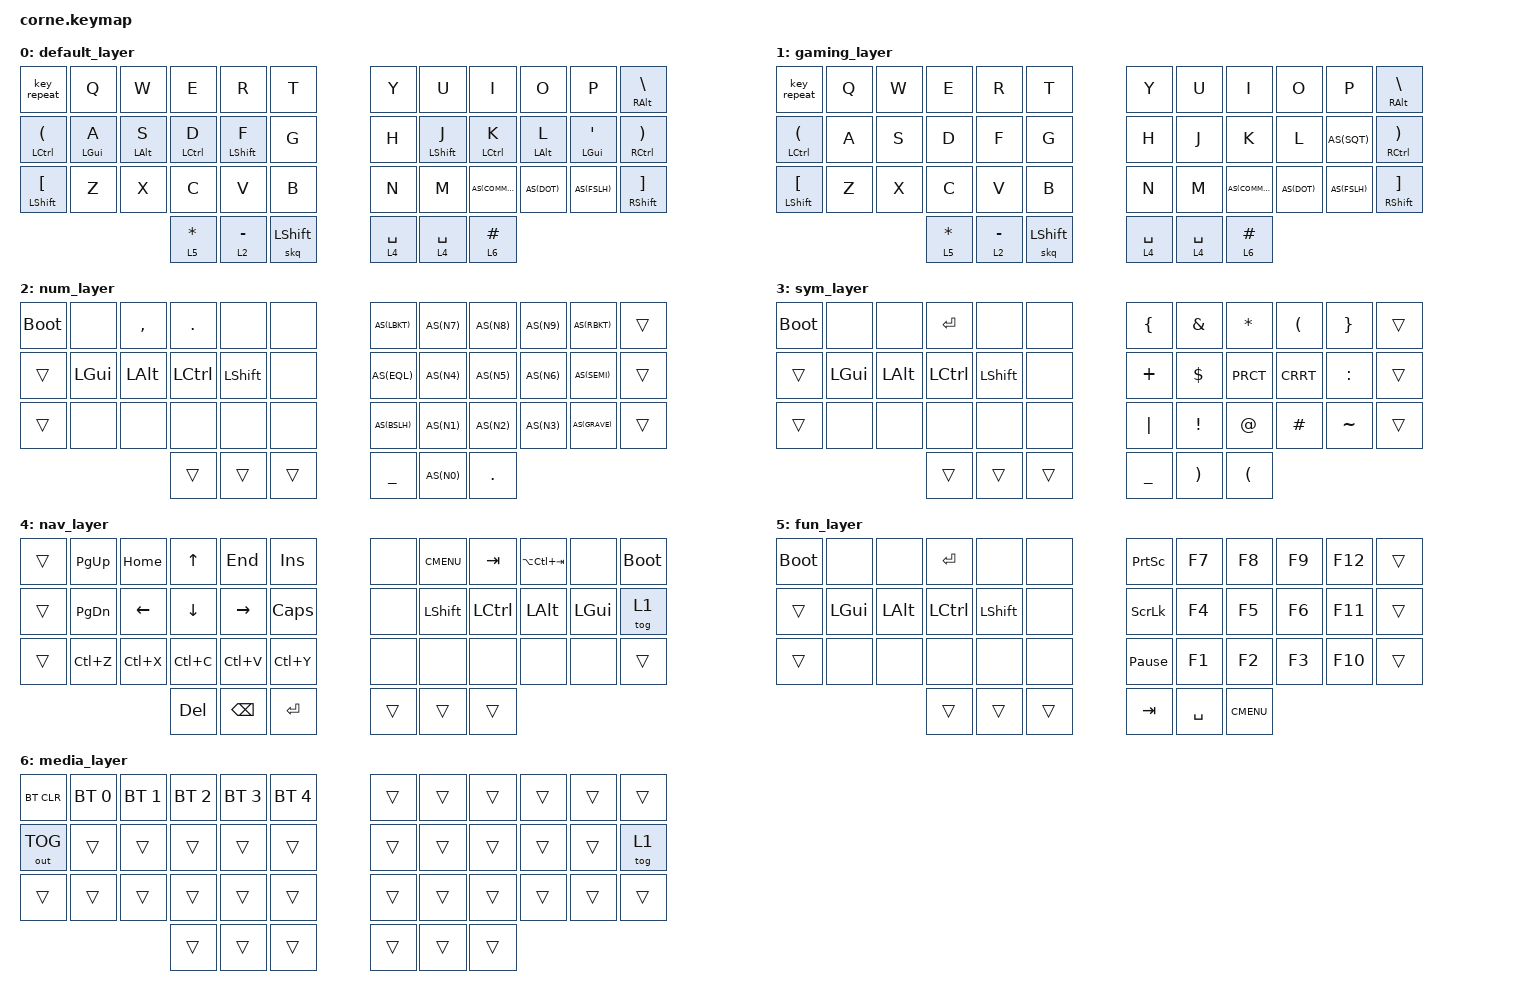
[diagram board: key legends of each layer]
/*
 * Copyright (c) 2020 The ZMK Contributors
 *
 * SPDX-License-Identifier: MIT
 */

#include <behaviors.dtsi>
#include <dt-bindings/zmk/keys.h>
#include <dt-bindings/zmk/bt.h>
#include <dt-bindings/zmk/outputs.h>


#define AS(keycode) &as LS(keycode) keycode

/ {
    behaviors {
      // auto shift behavior copied from: https://github.com/serebrov/zmk-config/blob/master/config/microdox.keymap#L23-L36
      as: auto_shift {
          compatible = "zmk,behavior-hold-tap";
          label = "AUTO_SHIFT";
          #binding-cells = <2>;
          tapping_term_ms = <200>;
          quick_tap_ms = <0>;
          flavor = "tap-preferred";
          bindings = <&kp>, <&kp>;
      };

      // Note: quick-release fixes the issue of sticky shift producing multiple upper case letters (see https://github.com/zmkfirmware/zmk/issues/903#issuecomment-909209198).
      skq: sticky_key_quick_release {
        compatible = "zmk,behavior-sticky-key";
        label = "STICKY_KEY_QUICK_RELEASE";
        #binding-cells = <1>;
        bindings = <&kp>;
        release-after-ms = <1000>;
        quick-release;
      };

      hm: homerow_mods {
          compatible = "zmk,behavior-hold-tap";
          label = "HOMEROW_MODS";
          #binding-cells = <2>;
          tapping-term-ms = <300>;
          quick-tap-ms = <0>;
          flavor = "tap-preferred";
          bindings = <&kp>, <&kp>;
      };
    };

    combos {
        compatible = "zmk,combos";
        combo_esc {
            timeout-ms = <50>;
            key-positions = <0 1>;
            bindings = <&kp ESC>;
        };

        combo_scrnsht {
            timeout-ms = <50>;
            key-positions = <1 25>;
            bindings = <&kp LG(LS(S))>;
        };

        combo_cut {
            timeout-ms = <50>;
            key-positions = <2 26>;
            bindings = <&kp LC(X)>;
        };

        combo_copy {
            timeout-ms = <50>;
            key-positions = <3 27>;
            bindings = <&kp LC(C)>;
        };

        combo_paste {
            timeout-ms = <50>;
            key-positions = <4 28>;
            bindings = <&kp LC(V)>;
        };

        combo_volmute {
            timeout-ms = <30>;
            key-positions = <13 25>;
            bindings = <&kp C_MUTE>;
        };

        combo_voldn {
            timeout-ms = <30>;
            key-positions = <14 26>;
            bindings = <&kp C_VOL_DN>;
        };

        combo_volup {
            timeout-ms = <30>;
            key-positions = <15 27>;
            bindings = <&kp C_VOL_UP>;
        };

        combo_pworkspace {
            timeout-ms = <30>;
            key-positions = <16 28>;
            bindings = <&kp LC(LG(LEFT))>;
        };

        combo_nworkspace {
            timeout-ms = <30>;
            key-positions = <17 29>;
            bindings = <&kp LC(LG(RIGHT))>;
        };

//        combo_lgui {
//            timeout-ms = <50>;
//            key-positions = <25 26>;
//            bindings = <&kp LGUI>;
//        };

        combo_alttab {
            timeout-ms = <50>;
            key-positions = <14 15 16>;
            bindings = <&kp LA(TAB)>;
        };

//        combo_guitab {
//            timeout-ms = <50>;
//            key-positions = <27 28 29>;
//            bindings = <&kp LG(TAB)>;
//        };

//        combo_altctrltab {
//            timeout-ms = <50>;
//            key-positions = <3 4 5>;
//            bindings = <&kp LA(LC(TAB))>;
//        };

        combo_ret {
            timeout-ms = <50>;
            key-positions = <26 27>;
            bindings = <&kp RET>;
        };

        combo_bspc {
            timeout-ms = <30>;
            key-positions = <20 31>;
            bindings = <&kp BSPC>;
        };

        combo_bspc2 {
            timeout-ms = <30>;
            key-positions = <15 28>;
            bindings = <&kp BSPC>;
        };

        combo_ctrl {
            timeout-ms = <30>;
            key-positions = <20 21>;
            bindings = <&sk LCTRL>;
        };

        combo_cbspc {
            timeout-ms = <50>;
            key-positions = <20 21 31>;
            bindings = <&kp LC(BSPC)>;
        };

        combo_del {
            timeout-ms = <30>;
            key-positions = <20 33>;
            bindings = <&kp DELETE>;
        };

        combo_del2 {
            timeout-ms = <30>;
            key-positions = <15 26>;
            bindings = <&kp DELETE>;
        };

        combo_tab {
            timeout-ms = <50>;
            key-positions = <32 33>;
            bindings = <&kp TAB>;
        };
    };

    keymap {
      compatible = "zmk,keymap";

                default_layer {
// ------------------------------------------------------------------------------------------------------------
// |REPEAT |  Q  |  W  |  E   |   R   |  T     |    |  Y    |  U   |  I    |  O   |   P   |   \   |
// | LCTRL |  A  |  S  |  D   |   F   |  G     |    |  H    |  J   |  K    |  L   |   '   | RCTRL |
// | SHIFT |  Z  |  X  |  C   |   V   |  B     |    |  N    |  M   |  ,    |  .   |   /   | SHIFT |
//                       | *   |  -   | sticky-|    | SPC   | SPC | #     |
//                 hold: | FUN | NUM  | -shift |    | NAV   | NAV | MEDIA |
                      bindings = <
  &key_repeat     &kp Q      &kp W       &kp E       &kp R         &kp T        &kp Y        &kp U         &kp I        &kp O       &kp P          &mt RALT BSLH
  &mt LCTRL LPAR  &hm LGUI A &hm LALT S  &hm LCTRL D &hm LSHIFT F  &kp G        &kp H        &hm LSHIFT J  &hm LCTRL K  &hm LALT L  &hm LGUI SQT   &mt RCTRL RPAR
  &mt LSHFT LBKT  &kp Z      &kp X       &kp C       &kp V         &kp B        &kp N        &kp M         AS(COMMA)    AS(DOT)     AS(FSLH)       &mt RSHFT RBKT
                                    &lt 5 ASTRK  &lt 2 MINUS  &skq LSHFT    &lt 4 SPACE  &lt 4 SPACE  &lt 6 HASH
                        >;
                };


                gaming_layer {
// ------------------------------------------------------------------------------------------------------------
// |REPEAT |  Q  |  W  |  E   |   R   |  T     |    |  Y    |  U   |  I    |  O   |   P   |   \   |
// | LCTRL |  A  |  S  |  D   |   F   |  G     |    |  H    |  J   |  K    |  L   |   '   | RCTRL |
// | SHIFT |  Z  |  X  |  C   |   V   |  B     |    |  N    |  M   |  ,    |  .   |   /   | SHIFT |
//                       | *   |  -   | sticky-|    | SPC   | SPC | #     |
//                 hold: | FUN | NUM  | -shift |    | NAV   | NAV | MEDIA |
                      bindings = <
  &key_repeat     &kp Q     &kp W     &kp E      &kp R         &kp T        &kp Y        &kp U       &kp I       &kp O     &kp P     &mt RALT BSLH
  &mt LCTRL LPAR  &kp A     &kp S     &kp D      &kp F         &kp G        &kp H        &kp J       &kp K       &kp L     AS(SQT)   &mt RCTRL RPAR
  &mt LSHFT LBKT  &kp Z     &kp X     &kp C      &kp V         &kp B        &kp N        &kp M       AS(COMMA)   AS(DOT)   AS(FSLH)  &mt RSHFT RBKT
                                    &lt 5 ASTRK  &lt 2 MINUS  &skq LSHFT    &lt 4 SPACE  &lt 4 SPACE  &lt 6 HASH
                        >;
                };


                num_layer {
      bindings = <
  &bootloader &none     &kp COMMA  &kp DOT    &none       &none      AS(LBKT)   AS(N7)  AS(N8)  AS(N9)  AS(RBKT)  &trans
  &trans      &kp LGUI  &kp LALT   &kp LCTRL  &kp LSHFT   &none      AS(EQL)    AS(N4)  AS(N5)  AS(N6)  AS(SEMI)  &trans
  &trans      &none     &none      &none      &none       &none      AS(BSLH)   AS(N1)  AS(N2)  AS(N3)  AS(GRAVE) &trans
                                   &trans     &trans      &trans     &kp UNDER  AS(N0)  &kp DOT
                        >;
                };



                sym_layer {
// There is currently no way to access the SYM layer,
// but it's equivalent to the shifted NUM layer (which also has autoshift enabled,
// and also has a Shift on the "F" key), so it's redundant in that way...
      bindings = <
  &bootloader &none     &none      &kp RET    &none       &none      &kp LBRC   &kp AMPS  &kp ASTRK  &kp LPAR  &kp RBRC   &trans
  &trans      &kp LGUI  &kp LALT   &kp LCTRL  &kp LSHFT   &none      &kp PLUS   &kp DLLR  &kp PRCT   &kp CRRT  &kp COLON  &trans
  &trans      &none     &none      &none      &none       &none      &kp PIPE   &kp EXCL  &kp AT     &kp HASH  &kp TILDE  &trans
                                   &trans     &trans      &trans     &kp UNDER  &kp RPAR  &kp LPAR
                        >;
                };




                nav_layer {
      bindings = <
  &trans  &kp PG_UP   &kp HOME    &kp UP      &kp END     &kp INSERT       &none  &kp K_CMENU  &kp TAB    &kp LA(LC(TAB))  &none     &bootloader
  &trans  &kp PG_DN   &kp LEFT    &kp DOWN    &kp RIGHT   &kp CAPSLOCK     &none  &kp LSHFT    &kp LCTRL  &kp LALT         &kp LGUI  &tog 1
  &trans  &kp LC(Z)   &kp LC(X)   &kp LC(C)   &kp LC(V)   &kp LC(Y)        &none  &none        &none      &none            &none     &trans
                                  &kp DEL     &kp BSPC    &kp RET          &trans &trans       &trans
                        >;
                };



                fun_layer {
      bindings = <
  &bootloader &none     &none      &kp RET    &none       &none      &kp PSCRN        &kp F7   &kp F8  &kp F9  &kp F12  &trans
  &trans      &kp LGUI  &kp LALT   &kp LCTRL  &kp LSHFT   &none      &kp SLCK         &kp F4   &kp F5  &kp F6  &kp F11  &trans
  &trans      &none     &none      &none      &none       &none      &kp PAUSE_BREAK  &kp F1   &kp F2  &kp F3  &kp F10  &trans
                                   &trans     &trans      &trans     &kp TAB          &kp SPC  &kp K_CMENU
                        >;
                };




                media_layer {
// ------------------------------------------------------------------------------------------------------------
// | BTCLR | BT1 | BT2 |  BT3 |  BT4 |  BT5    |   |      |       |       |        |          |       |
// |OUT_TOG|     |     |      |      |         |   |      |       |       |        |          |       | DVORAK
// |       |     |     |      |      |         |   |      |       |       |        |          |       |
//                     |      |      |         |   |      |       |       |
      bindings = <
  &bt BT_CLR     &bt BT_SEL 0   &bt BT_SEL 1      &bt BT_SEL 2  &bt BT_SEL 3 &bt BT_SEL 4    &trans   &trans   &trans   &trans   &trans   &trans
  &out OUT_TOG   &trans         &trans            &trans        &trans       &trans          &trans   &trans   &trans   &trans   &trans   &tog 1
  &trans         &trans         &trans            &trans        &trans       &trans          &trans   &trans   &trans   &trans   &trans   &trans
                                                  &trans        &trans       &trans          &trans   &trans   &trans
                        >;
                };

        };
};
